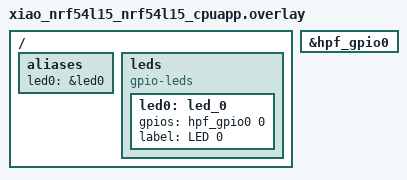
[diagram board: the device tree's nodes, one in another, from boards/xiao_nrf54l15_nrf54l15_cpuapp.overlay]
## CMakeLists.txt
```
# SPDX-License-Identifier: Apache-2.0
# Blinky with HPF GPIO Test

cmake_minimum_required(VERSION 3.20.0)

find_package(Zephyr REQUIRED HINTS $ENV{ZEPHYR_BASE})
project(hpf_gpio_blinky)

target_sources(app PRIVATE src/main.c)
```

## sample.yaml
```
sample:
  name: HPF GPIO Blinky Test
  description: Test GPIO via HPF framework on FLPR core
tests:
  sample.hpf.gpio_blinky:
    tags: gpio hpf blinky
    platform_allow: xiao_nrf54l15_nrf54l15_cpuapp
    integration_platforms:
      - xiao_nrf54l15_nrf54l15_cpuapp
    harness: console
    harness_config:
      type: multi_line
      regex:
        - "LED configured successfully"
        - "LED: ON"
        - "LED: OFF"
```

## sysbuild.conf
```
# SPDX-License-Identifier: Apache-2.0
# HPF GPIO Blinky configuration

# Enable HPF and GPIO
SB_CONFIG_HPF=y
SB_CONFIG_HPF_GPIO=y
SB_CONFIG_HPF_GPIO_BACKEND_ICMSG=y

# Disable default VPR launcher
SB_CONFIG_VPR_LAUNCHER=n

# Disable Partition Manager
SB_CONFIG_PARTITION_MANAGER=n

# GPIO will run on FLPR core
SB_CONFIG_HPF_GPIO_REMOTE_BOARD="xiao_nrf54l15/nrf54l15/cpuflpr"
```

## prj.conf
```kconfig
# SPDX-License-Identifier: Apache-2.0
# HPF GPIO Blinky - Application Core Configuration

# IPC for communication with FLPR core
CONFIG_MBOX=y
CONFIG_IPC_SERVICE=y
CONFIG_IPC_SERVICE_BACKEND_ICMSG=y

# GPIO
CONFIG_GPIO=y

# Logging (minimal for blinky)
CONFIG_LOG=y
CONFIG_LOG_DEFAULT_LEVEL=2
```

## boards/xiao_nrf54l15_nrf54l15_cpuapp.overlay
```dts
/*
 * SPDX-License-Identifier: Apache-2.0
 * 
 * HPF GPIO device tree overlay for XIAO nRF54L15
 * Maps GPIO through HPF (FLPR core)
 */

/ {
	aliases {
		led0 = &led0;
	};

	leds {
		compatible = "gpio-leds";
		led0: led_0 {
			gpios = <&hpf_gpio0 0 GPIO_ACTIVE_HIGH>;  /* Use HPF GPIO port */
			label = "LED 0";
		};
	};
};

/* Define HPF GPIO controller */
&hpf_gpio0 {
	status = "okay";
};
```

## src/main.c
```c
/*
 * SPDX-License-Identifier: Apache-2.0
 * 
 * Blinky using HPF GPIO on FLPR core
 * Based on Zephyr blinky sample
 */

#include <zephyr/kernel.h>
#include <zephyr/drivers/gpio.h>
#include <zephyr/logging/log.h>

LOG_MODULE_REGISTER(hpf_gpio_blinky, LOG_LEVEL_INF);

/* Use the onboard LED (LED0) */
#define LED0_NODE DT_ALIAS(led0)

static const struct gpio_dt_spec led = GPIO_DT_SPEC_GET(LED0_NODE, gpios);

int main(void)
{
	int ret;
	bool led_state = true;

	LOG_INF("===========================================");
	LOG_INF("HPF GPIO Blinky Test");
	LOG_INF("Testing GPIO via FLPR core");
	LOG_INF("===========================================");

	if (!gpio_is_ready_dt(&led)) {
		LOG_ERR("LED GPIO device not ready");
		return -1;
	}

	ret = gpio_pin_configure_dt(&led, GPIO_OUTPUT_ACTIVE);
	if (ret < 0) {
		LOG_ERR("Failed to configure LED pin: %d", ret);
		return ret;
	}

	LOG_INF("LED configured successfully on %s pin %d", 
			led.port->name, led.pin);
	LOG_INF("Starting blink loop...");

	while (1) {
		ret = gpio_pin_toggle_dt(&led);
		if (ret < 0) {
			LOG_ERR("Failed to toggle LED: %d", ret);
			return ret;
		}

		led_state = !led_state;
		LOG_INF("LED: %s", led_state ? "ON" : "OFF");
		
		k_msleep(1000);
	}

	return 0;
}
```
